# RESTORE_CM1 register map
Vendor: Texas Instruments
Peripheral module from a debugger description file (folder omap4430).
Registers are 32-bit, access per field, reset 0x0 unless marked. A register's access mark holds for its fields unless they carry their own. Offsets are as the file gives them; lines under a group give offsets from that group; [hi:lo] are bit positions; {n}, {i} and the like mark numbered series; 'fields as' and 'values as' point back to an identical list; <NAME> marks a mode.

## RESTORE_CM1
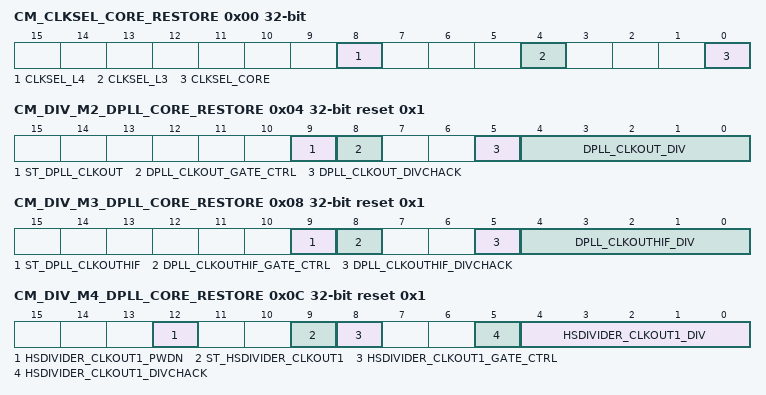
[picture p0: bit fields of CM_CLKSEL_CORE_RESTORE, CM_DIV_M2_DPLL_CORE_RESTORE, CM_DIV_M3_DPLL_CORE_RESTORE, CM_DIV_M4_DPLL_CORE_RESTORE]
0x00 CM_CLKSEL_CORE_RESTORE — Second address map for register. Used only by automatic restore upon wakeup from device OFF mode.
  [8] CLKSEL_L4 rw — Selects L4 interconnect clock (L4_clk)
    0=L4_CLK is L3_CLK divided by 1; 1=L4_CLK is L3_CLK divided by 2
  [4] CLKSEL_L3 rw — Selects L3 interconnect clock (L3_clk)
    0=L3_CLK is CORE_CLK divided by 1; 1=L3_CLK is CORE_CLK divided by 2
  [0] CLKSEL_CORE rw — Selects CORE_CLK configuration
    0=CORE_CLK is CORE_X2_CLK divided by 1; 1=CORE_CLK is CORE_X2_CLK divided by 2
0x04 CM_DIV_M2_DPLL_CORE_RESTORE reset 0x1 — Second address map for register. Used only by automatic restore upon wakeup from device OFF mode.
  [9] ST_DPLL_CLKOUT ro — DPLL CLKOUT status
    0=ST_DPLL_CLKOUT_0_r (The clock output is enabled); 1=ST_DPLL_CLKOUT_1_r (The clock output is gated)
  [8] DPLL_CLKOUT_GATE_CTRL rw — Control gating of DPLL CLKOUT
    0=Automatically gate this clock when there is no dependency for it; 1=Force this clock to stay enabled even if there is no request
  [5] DPLL_CLKOUT_DIVCHACK ro — Toggle on this status bit after changing DPLL_CLKOUT_DIV indicates that the change in divider value has taken effect
  [4:0] DPLL_CLKOUT_DIV rw — DPLL post-divider factor, M2, for internal clock generation (1 to 31); Divide value from 1 to 31.
0x08 CM_DIV_M3_DPLL_CORE_RESTORE reset 0x1 — Second address map for register. Used only by automatic restore upon wakeup from device OFF mode.
  [9] ST_DPLL_CLKOUTHIF ro — DPLL CLKOUTHIF status
    0=ST_DPLL_CLKOUTHIF_0_r (The clock output is enabled); 1=ST_DPLL_CLKOUTHIF_1_r (The clock output is gated)
  [8] DPLL_CLKOUTHIF_GATE_CTRL rw — Control gating of DPLL CLKOUTHIF
    values as CM_DIV_M2_DPLL_CORE_RESTORE.DPLL_CLKOUT_GATE_CTRL
  [5] DPLL_CLKOUTHIF_DIVCHACK ro — Toggle on this status bit after changing DPLL_CLKOUTHIF_DIV indicates that the change in divider value has taken effect
  [4:0] DPLL_CLKOUTHIF_DIV rw — DPLL post-divider factor, M3, for internal clock generation (1 to 31);Divide value from 1 to 31.
0x0C CM_DIV_M4_DPLL_CORE_RESTORE reset 0x1 — Second address map for register. Used only by automatic restore upon wakeup from device OFF mode.
  [12] HSDIVIDER_CLKOUT1_PWDN ro — Automatic power down for HSDIVIDER M4 divider and hence CLKOUT1 output when the o/p clock is gated.
    0=HSDIVIDER_CLKOUT1_PWDN_0_r (Keep M4 divider powered on even when CLKOUT1 is gated.)
  [9] ST_HSDIVIDER_CLKOUT1 ro — HSDIVIDER CLKOUT1 status
    0=ST_HSDIVIDER_CLKOUT1_0_r (The clock output is gated); 1=ST_HSDIVIDER_CLKOUT1_1_r (The clock output is enabled)
  [8] HSDIVIDER_CLKOUT1_GATE_CTRL rw — Control gating of HSDIVIDER CLKOUT1
    values as CM_DIV_M2_DPLL_CORE_RESTORE.DPLL_CLKOUT_GATE_CTRL
  [5] HSDIVIDER_CLKOUT1_DIVCHACK ro — Toggle on this status bit after changing HSDIVIDER_CLKOUT1_DIV indicates that the change in divider value has taken effect
  [4:0] HSDIVIDER_CLKOUT1_DIV rw — DPLL M4 post-divider factor (1 to 31).
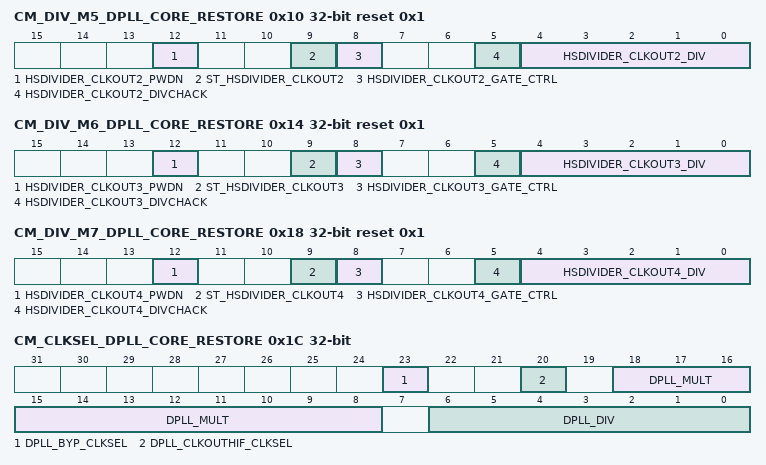
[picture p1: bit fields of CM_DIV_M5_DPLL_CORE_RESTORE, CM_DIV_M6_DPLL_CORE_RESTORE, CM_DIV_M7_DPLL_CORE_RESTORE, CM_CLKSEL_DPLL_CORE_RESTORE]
0x10 CM_DIV_M5_DPLL_CORE_RESTORE reset 0x1 — Second address map for register. Used only by automatic restore upon wakeup from device OFF mode.
  [12] HSDIVIDER_CLKOUT2_PWDN ro — Automatic power down for HSDIVIDER M5 divider and hence CLKOUT2 output when the o/p clock is gated.
    0=HSDIVIDER_CLKOUT2_PWDN_0_r (Keep M5 divider powered on even when CLKOUT2 is gated.)
  [9] ST_HSDIVIDER_CLKOUT2 ro — HSDIVIDER CLKOUT2 status
    0=ST_HSDIVIDER_CLKOUT2_0_r (The clock output is gated); 1=ST_HSDIVIDER_CLKOUT2_1_r (The clock output is enabled)
  [8] HSDIVIDER_CLKOUT2_GATE_CTRL rw — Control gating of HSDIVIDER CLKOUT2
    values as CM_DIV_M2_DPLL_CORE_RESTORE.DPLL_CLKOUT_GATE_CTRL
  [5] HSDIVIDER_CLKOUT2_DIVCHACK ro — Toggle on this status bit after changing HSDIVIDER_CLKOUT2_DIV indicates that the change in divider value has taken effect
  [4:0] HSDIVIDER_CLKOUT2_DIV rw — DPLL M5 post-divider factor (1 to 31).
0x14 CM_DIV_M6_DPLL_CORE_RESTORE reset 0x1 — Second address map for register. Used only by automatic restore upon wakeup from device OFF mode.
  [12] HSDIVIDER_CLKOUT3_PWDN ro — Automatic power down for HSDIVIDER M6 divider and hence CLKOUT3 output when the o/p clock is gated.
    0=HSDIVIDER_CLKOUT3_PWDN_0_r (Keep M6 divider powered on even when CLKOUT3 is gated.)
  [9] ST_HSDIVIDER_CLKOUT3 ro — HSDIVIDER CLKOUT3 status
    0=ST_HSDIVIDER_CLKOUT3_0_r (The clock output is gated); 1=ST_HSDIVIDER_CLKOUT3_1_r (The clock output is enabled)
  [8] HSDIVIDER_CLKOUT3_GATE_CTRL rw — Control gating of HSDIVIDER CLKOUT3
    values as CM_DIV_M2_DPLL_CORE_RESTORE.DPLL_CLKOUT_GATE_CTRL
  [5] HSDIVIDER_CLKOUT3_DIVCHACK ro — Toggle on this status bit after changing HSDIVIDER_CLKOUT3_DIV indicates that the change in divider value has taken effect
  [4:0] HSDIVIDER_CLKOUT3_DIV rw — DPLL M6 post-divider factor (1 to 31).
0x18 CM_DIV_M7_DPLL_CORE_RESTORE reset 0x1 — Second address map for register. Used only by automatic restore upon wakeup from device OFF mode.
  [12] HSDIVIDER_CLKOUT4_PWDN ro — Automatic power down for HSDIVIDER M7 divider and hence CLKOUT4 output when the o/p clock is gated.
    0=HSDIVIDER_CLKOUT4_PWDN_0_r (Keep M7 divider powered on even when CLKOUT4 is gated.)
  [9] ST_HSDIVIDER_CLKOUT4 ro — HSDIVIDER CLKOUT4 status
    0=ST_HSDIVIDER_CLKOUT4_0_r (The clock output is gated); 1=ST_HSDIVIDER_CLKOUT4_1_r (The clock output is enabled)
  [8] HSDIVIDER_CLKOUT4_GATE_CTRL rw — Control gating of HSDIVIDER CLKOUT4
    values as CM_DIV_M2_DPLL_CORE_RESTORE.DPLL_CLKOUT_GATE_CTRL
  [5] HSDIVIDER_CLKOUT4_DIVCHACK ro — Toggle on this status bit after changing HSDIVIDER_CLKOUT4_DIV indicates that the change in divider value has taken effect
  [4:0] HSDIVIDER_CLKOUT4_DIV rw — DPLL M7 post-divider factor (1 to 31).
0x1C CM_CLKSEL_DPLL_CORE_RESTORE — Second address map for register. Used only by automatic restore upon wakeup from device OFF mode.
  [23] DPLL_BYP_CLKSEL rw — Allows control of the BYPASS clock of the PLL and the associated HSDIVIDER. Same as ULOWCLKEN on DPLL. In DPLL Locked mode, 0 - No impact 1 - No impact In DPLL Bypass mode, 0 - CLKINP is selected as the BYPASS clock for CLKOUT/CLKOUTX2 1 - CLKINPULOW is selected as the BYPASS clock for CLKOUT/CLKOUTX2
  [20] DPLL_CLKOUTHIF_CLKSEL rw — Selects the source of the DPLL CLKOUTHIF clock. Same as CLKINPHIFSEL pin on the DPLL
    0=CLKOUTHIF is generated from the DPLL oscillator (DCO); 1=CLKOUTHIF is generated from CLKINPHIF
  [18:8] DPLL_MULT rw — DPLL multiplier factor (2 to 2047). This register is automatically cleared to 0 when the DPLL_EN field in the *CLKMODE_DPLL* register is set to select MN bypass mode. (equal to input M of DPLL; M=2 to 2047 = DPLL multiplies by M).
  [6:0] DPLL_DIV rw — DPLL divider factor (0 to 127) (equal to input N of DPLL; actual division factor is N+1).
0x20 CM_SSC_DELTAMSTEP_DPLL_CORE_RESTORE — Second address map for register. Used only by automatic restore upon wakeup from device OFF mode. [warm reset insensitive]
  [19:0] DELTAMSTEP rw — DeltaMStep is split into fractional and integer part. For Triangular Spread Spectrum: [19:18] for integer part, [17:0] for fractional part For Square Wave Spread Spectrum [19:14] for integer part, [13:0] for fractional part
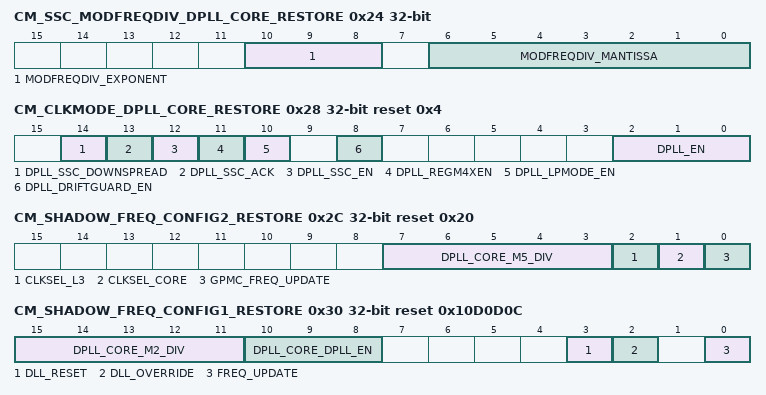
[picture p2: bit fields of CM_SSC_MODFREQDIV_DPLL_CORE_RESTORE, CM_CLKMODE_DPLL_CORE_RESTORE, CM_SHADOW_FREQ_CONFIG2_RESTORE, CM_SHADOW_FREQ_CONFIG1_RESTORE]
0x24 CM_SSC_MODFREQDIV_DPLL_CORE_RESTORE — Second address map for register. Used only by automatic restore upon wakeup from device OFF mode. [warm reset insensitive]
  [10:8] MODFREQDIV_EXPONENT rw — Set the Exponent component of MODFREQDIV factor
  [6:0] MODFREQDIV_MANTISSA rw — Set the Mantissa component of MODFREQDIV factor
0x28 CM_CLKMODE_DPLL_CORE_RESTORE reset 0x4 — Second address map for register. Used only by automatic restore upon wakeup from device OFF mode.
  [14] DPLL_SSC_DOWNSPREAD rw — Control if only low frequency spread is required
    0=When SSC is enabled, clock frequency is spread on both sides of the programmed frequency; 1=When SSC is enabled, clock frequency is spread only on the lower side of the programmed frequency
  [13] DPLL_SSC_ACK ro — Acknowledgement from the DPLL regarding start and stop of Spread Spectrum Clocking feature
    0=DPLL_SSC_ACK_0_r (SSC has been turned off on PLL o/ps); 1=DPLL_SSC_ACK_1_r (SSC has been turned on on PLL o/ps)
  [12] DPLL_SSC_EN rw — Enable or disable Spread Spectrum Clocking
    0=SSC disabled; 1=SSC enabled
  [11] DPLL_REGM4XEN ro — Enable the REGM4XEN mode of the DPLL. Please check the DPLL documentation to check when this mode can be enabled.
    0=DPLL_REGM4XEN_0_r (REGM4XEN mode of the DPLL is disabled)
  [10] DPLL_LPMODE_EN rw — Set the DPLL in low-power mode. Check the DPLL documentation to see when this can be enabled.
    0=Low-power mode of the DPLL is disabled; 1=Low-power mode of the DPLL is enabled
  [8] DPLL_DRIFTGUARD_EN rw — This bit allows to enable or disable the automatic recalibration feature of the DPLL. The DPLL will automatically start a recalibration process upon assertion of the DPLL's RECAL flag if this bit is set.
    0=DRIFTGUARD feature is disabled; 1=DRIFTGUARD feature is enabled
  [2:0] DPLL_EN rw — DPLL control. Upon Warm Reset, the PRCM DPLL control state machine updates this register to reflect MN bypass mode.
    4=Put the DPLL in MN bypass mode. The DPLL_MULT register bits are reset to 0 automatically by putting the DPLL in this mode.; 5=Put the DPLL in idle bypass low-power mode; 6=Put the DPLL in idle bypass fast-relock mode; 7=Enables the DPLL in lock mode
0x2C CM_SHADOW_FREQ_CONFIG2_RESTORE reset 0x20 — Second address map for register. Used only by automatic restore upon wakeup from device OFF mode.
  [7:3] DPLL_CORE_M5_DIV rw — Shadow register forCM_DIV_M5_DPLL_CORE.HSDIVIDER_CLKOUT2_DIV. The main register is automatically loaded with the shadow register value after GPMC IDLE if the CM_SHADOW_FREQ_CONFIG1.FREQ_UPDATE field is set to 1 and GPMC_FREQ_UPDATE is set to 1. Divide value from 1 to 31.
  [2] CLKSEL_L3 rw — Shadow register forCM_CLKSEL_CORE.CLKSEL_L3. The main register is automatically loaded with the shadow register value after GPMC IDLE if the CM_SHADOW_FREQ_CONFIG1.FREQ_UPDATE field is set to 1 and GPMC_FREQ_UPDATE is set to 1.
    values as CM_CLKSEL_CORE_RESTORE.CLKSEL_L3
  [1] CLKSEL_CORE rw — Shadow register forCM_CLKSEL_CORE.CLKSEL_CORE. The main register is automatically loaded with the shadow register value after GPMC IDLE if the CM_SHADOW_FREQ_CONFIG1.FREQ_UPDATE field is set to 1 and GPMC_FREQ_UPDATE is set to 1.
    values as CM_CLKSEL_CORE_RESTORE.CLKSEL_CORE
  [0] GPMC_FREQ_UPDATE rw — Controls whether or not GPMC has to be put automatically into idle during the frequency change operation.
    0=GPMC is not put automatically into idle during frequency change operation; 1=GPMC is put automatically into idle during frequency change operation
0x30 CM_SHADOW_FREQ_CONFIG1_RESTORE access not given reset 0x10D0D0C — Second address map for register. Used only by automatic restore upon wakeup from device OFF mode.
  [15:11] DPLL_CORE_M2_DIV rw — Shadow register forCM_DIV_M2_DPLL_CORE.DPLL_CLKOUT_DIV. The main register is automatically loaded with the shadow register value after EMIF IDLE if the FREQ_UPDATE field is set to 1. Divide value from 1 to 31.
  [10:8] DPLL_CORE_DPLL_EN rw — Shadow register forCM_CLKMODE_DPLL_CORE.DPLL_EN. The main register is automatically loaded with the shadow register value after EMIF IDLE if the FREQ_UPDATE field is set to 1.
    values as CM_CLKMODE_DPLL_CORE_RESTORE.DPLL_EN
  [3] DLL_RESET rw — Specify if DLL should be reset or not during the frequency change hardware sequence.
    0=DLL is not reset during the frequency change hardware sequence; 1=DLL is reset automatically during the frequency change hardware sequence
  [2] DLL_OVERRIDE rw — Shadow register forCM_DLL_CTRL.DLL_OVERRIDE.The main register is automatically loaded with the shadow register value after EMIF IDLE if the FREQ_UPDATE field is set to 1.
    0=Lock and code outputs are not overriden; 1=Lock output is overriden to 1 and code output is overriden with a value coming from control module
  [0] FREQ_UPDATE — Writing 1 indicates that a new configuration is available. It is automatically cleared by h/w after the configuration has been applied. (access RW WSpecial)
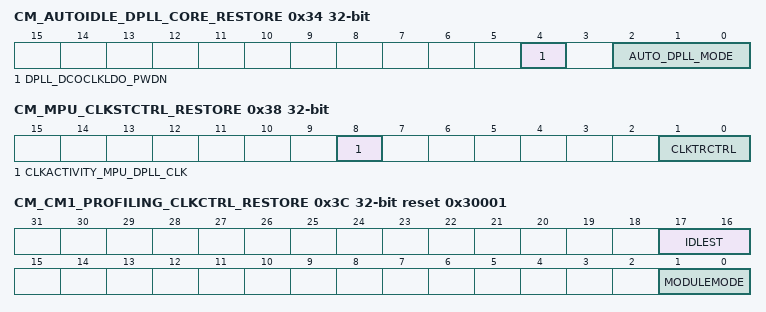
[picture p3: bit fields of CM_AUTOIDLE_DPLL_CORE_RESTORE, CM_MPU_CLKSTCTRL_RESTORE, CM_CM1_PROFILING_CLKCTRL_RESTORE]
0x34 CM_AUTOIDLE_DPLL_CORE_RESTORE — Second address map for register. Used only by automatic restore upon wakeup from device OFF mode.
  [4] DPLL_DCOCLKLDO_PWDN rw — Allows powering down the DCOCLKLDO o/p of DPLL if all dividers in HSDIVIDER are powered down. PRCM takes care of reenabling this path for either restarting HSDIVIDER o/p or entering bypass mode.
    0=Keep DCOCLKLDO powered even when all dividers in HSDIVIDER are powered down; 1=Automatically power down DCOCLKLDO when all o/ps of HSDIVIDER are powered down
  [2:0] AUTO_DPLL_MODE rw — DPLL automatic control.
    0=DPLL auto control disabled; 1=The DPLL is automatically put in low-power stop mode when its DPLL generated clocks are not required anymore. It is also restarted automatically.; 2=The DPLL is automatically put in fast-relock stop mode when its DPLL generated clocks are not required anymore. It is also restarted automatically.; 5=The DPLL is automatically put in idle bypass low-power mode when its DPLL generated clocks are not required anymore. It is also restarted automatically.; 6=The DPLL is automatically put in idle bypass fast-relock mode when its DPLL generated clocks are not required anymore. It is also restarted automatically.
0x38 CM_MPU_CLKSTCTRL_RESTORE — Second address map for register. Used only by automatic restore upon wakeup from device OFF mode.
  [8] CLKACTIVITY_MPU_DPLL_CLK ro — This field indicates the state of the MPU_DPLL_CLK clock in the domain. [warm reset insensitive]
    0=CLKACTIVITY_MPU_DPLL_CLK_0_r (Corresponding clock is definitely gated); 1=CLKACTIVITY_MPU_DPLL_CLK_1_r (Corresponding clock is running or gating/ungating transition is ongoing)
  [1:0] CLKTRCTRL rw — Controls the clock state transition of the MPU clock domain.
    0=NO_SLEEP: Sleep transition cannot be initiated. Wakeup transition may however occur.; 1=CLKTRCTRL_1_r (Reserved); 2=SW_WKUP: Start a software forced wake-up transition on the domain; 3=HW_AUTO: Automatic transition is enabled. Sleep and wakeup transition are based upon hardware conditions.
0x3C CM_CM1_PROFILING_CLKCTRL_RESTORE reset 0x30001 — Second address map for register. Used only by automatic restore upon wakeup from device OFF mode. [warm reset insensitive]
  [17:16] IDLEST ro — Module idle status
    3=IDLEST_3_r (Module is disabled); 2=IDLEST_2_r (Module is in Idle); 1=IDLEST_1_r (Module is performing transition: wakeup, or sleep, or sleep abortion); 0=IDLEST_0_r (Module is fully functional)
  [1:0] MODULEMODE rw — Control the way mandatory clocks are managed.
    0=Module is disabled by software. OCP configuration port is not accessible.; 1=Module is managed automatically by hadware along with CM1 and EMU domain. OCP configuration port is accessible only when EMU domain is on.; 2=MODULEMODE_2_r (Reserved); 3=MODULEMODE_3_r (Reserved)
0x40 CM_DYN_DEP_PRESCAL_RESTORE reset 0x20 — Second address map for register. Used only by automatic restore upon wakeup from device OFF mode.
  [5:0] PRESCAL rw — Time unit is equal to (PRESCAL + 1) L4 clock cycles.
